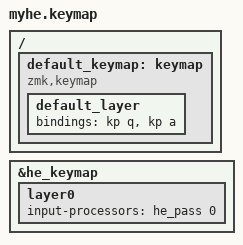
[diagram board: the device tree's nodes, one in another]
#include <behaviors.dtsi>
#include <dt-bindings/zmk/keys.h>
#include <dt-bindings/zmk/bt.h>

/ {
    default_keymap: keymap {
        compatible = "zmk,keymap";

        default_layer {
            //.overlay에서 정의한 8x8 매트릭스에 맞춰 64개 키를 정의합니다.
            // 아래는 Alice 배열 스타일의 예시입니다.
            bindings = <
                &kp q 
                &kp a
            >;
        };
    };
};

&he_keymap {
    layer0 {
        input-processors = <
            &he_pass 0
        >;
    };
};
